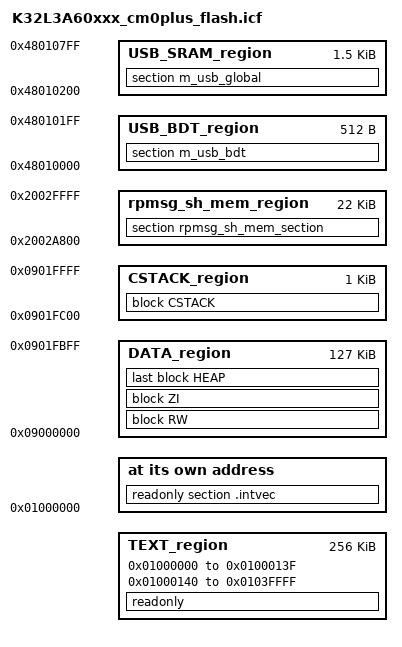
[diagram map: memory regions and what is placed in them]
/*
** ###################################################################
**     Processor:           K32L3A60VPJ1A_cm0plus
**     Compiler:            IAR ANSI C/C++ Compiler for ARM
**     Reference manual:    K32L3ARM, Rev. 0 , 05/2019
**     Version:             rev. 1.0, 2019-04-22
**     Build:               b191008
**
**     Abstract:
**         Linker file for the IAR ANSI C/C++ Compiler for ARM
**
**     Copyright 2016 Freescale Semiconductor, Inc.
**     Copyright 2016-2019 NXP
**     All rights reserved.
**
**     SPDX-License-Identifier: BSD-3-Clause
**
**     http:                 www.nxp.com
**     mail:                 support@nxp.com
**
** ###################################################################
*/

define symbol m_interrupts_start       = 0x01000000;
define symbol m_interrupts_end         = 0x0100013F;

define symbol m_text_start             = 0x01000140;
define symbol m_text_end               = 0x0103FFFF;

define symbol m_data_start             = 0x09000000;
define symbol m_data_end               = 0x0901FFFF;

if (isdefinedsymbol(__use_shmem__)) {
  define exported symbol rpmsg_sh_mem_start    = 0x2002A800;
  define exported symbol rpmsg_sh_mem_end      = 0x2002FFFF;
}

define symbol m_usb_sram_start         = 0x48010000;
define symbol m_usb_sram_end           = 0x480107FF;

/* USB BDT size */
define symbol usb_bdt_size             = 0x200;

/* Sizes */
if (isdefinedsymbol(__stack_size__)) {
  define symbol __size_cstack__        = __stack_size__;
} else {
  define symbol __size_cstack__        = 0x0400;
}

if (isdefinedsymbol(__heap_size__)) {
  define symbol __size_heap__          = __heap_size__;
} else {
  define symbol __size_heap__          = 0x0400;
}

define memory mem with size = 4G;
define region TEXT_region = mem:[from m_interrupts_start to m_interrupts_end]
                          | mem:[from m_text_start to m_text_end];
define region DATA_region = mem:[from m_data_start to m_data_end-__size_cstack__];
define region CSTACK_region = mem:[from m_data_end-__size_cstack__+1 to m_data_end];
if (isdefinedsymbol(__use_shmem__)) {
  define region rpmsg_sh_mem_region     = mem:[from rpmsg_sh_mem_start to rpmsg_sh_mem_end];
}

define block CSTACK    with alignment = 8, size = __size_cstack__   { };
define block HEAP      with alignment = 8, size = __size_heap__     { };
define block RW        { readwrite };
define block ZI        { zi };

/* regions for USB */
define region USB_BDT_region = mem:[from m_usb_sram_start to m_usb_sram_start + usb_bdt_size - 1];
define region USB_SRAM_region = mem:[from m_usb_sram_start + usb_bdt_size to m_usb_sram_end];
place in USB_BDT_region                     { section m_usb_bdt };
place in USB_SRAM_region                    { section m_usb_global };

initialize by copy { readwrite, section .textrw };
do not initialize  { section .noinit, section m_usb_bdt, section m_usb_global };
if (isdefinedsymbol(__use_shmem__)) {
  do not initialize  { section rpmsg_sh_mem_section };
}

place at address mem: m_interrupts_start    { readonly section .intvec };
place in TEXT_region                        { readonly };
place in DATA_region                        { block RW };
place in DATA_region                        { block ZI };
place in DATA_region                        { last block HEAP };
place in CSTACK_region                      { block CSTACK };
if (isdefinedsymbol(__use_shmem__)) {
  place in rpmsg_sh_mem_region                { section rpmsg_sh_mem_section };
}

